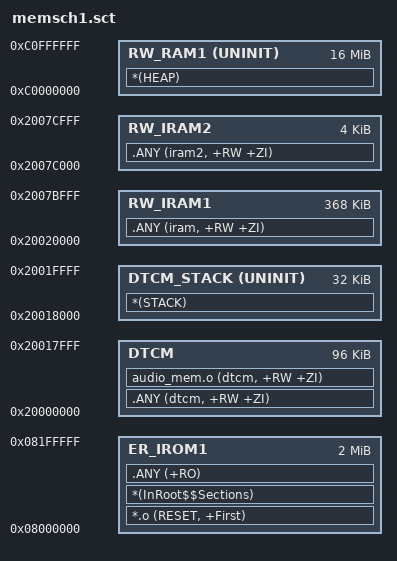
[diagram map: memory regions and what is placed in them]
; *************************************************************
; *** Scatter-Loading Description File generated by uVision ***
; *************************************************************

LR_IROM1 0x08000000 0x00200000  {    ; load region size_region
  ER_IROM1 0x08000000 0x00200000  {  ; load address = execution address
   *.o (RESET, +First)
   *(InRoot$$Sections)
   .ANY (+RO)
  }
  DTCM 0x20000000 0x00018000  {  ; DTCM
   .ANY (dtcm, +RW +ZI)
   audio_mem.o (dtcm, +RW +ZI)
   ;r_main.o (dtcm, +RW +ZI)
  }
  DTCM_STACK 0x20018000 UNINIT 0x00008000  {  ; DTCM
   *(STACK)
  }
  RW_IRAM1 0x20020000 0x0005C000  {  ; RW data
   .ANY (iram, +RW +ZI)
  }
  RW_IRAM2 0x2007C000 0x00001000  {  ; RW data
   .ANY (iram2, +RW +ZI)
  }
  RW_RAM1 0xC0000000 UNINIT 0x01000000  { ; External SDRAM
   *(HEAP)
  }
}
